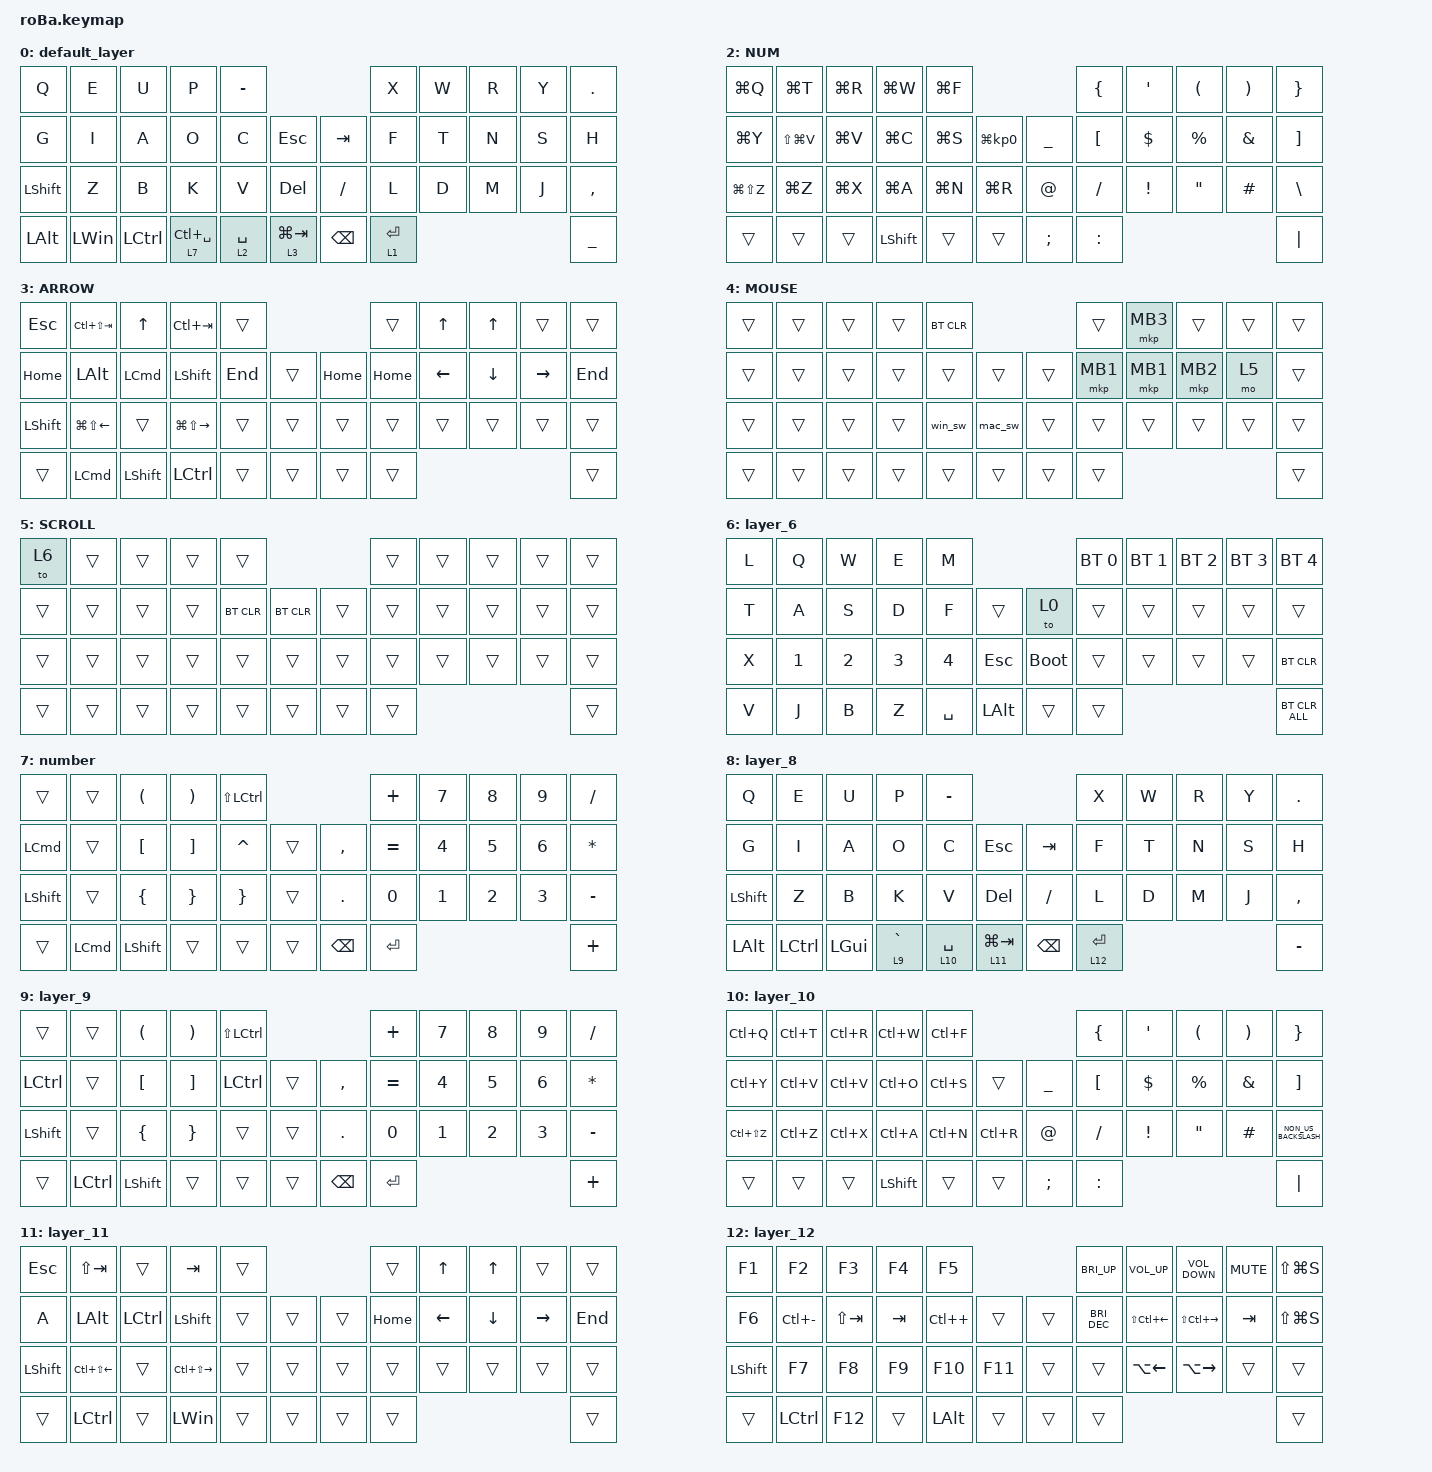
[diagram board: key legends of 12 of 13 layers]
#include <behaviors.dtsi>
#include <dt-bindings/zmk/bt.h>
#include <dt-bindings/zmk/keys.h>
#include <dt-bindings/zmk/pointing.h>

&mt {
    flavor = "balanced";
    quick-tap-ms = <0>;
};

&trackball {
    automouse-layer = <4>;
    scroll-layers = <5>;

    // arrows {
    //     layers = <3>;
    //     bindings =
    //         <&kp RIGHT_ARROW>,
    //         <&kp LEFT_ARROW>,
    //         <&kp UP_ARROW>,
    //         <&kp DOWN_ARROW>;
    //     tick = <10>;
    //     wait-ms = <5>;
    //     tap-ms = <5>;
    // };
};

/ {
    combos { compatible = "zmk,combos"; };

    macros {
        to_layer_0: to_layer_0 {
            compatible = "zmk,behavior-macro-one-param";
            #binding-cells = <1>;
            bindings = <&to 0 &macro_param_1to1 &kp MACRO_PLACEHOLDER>;
            label = "TO_LAYER_0";
        };

        mac_sw: mac_sw {
            compatible = "zmk,behavior-macro";
            #binding-cells = <0>;
            bindings = <&bt BT_SEL 0 &to 0>;
            label = "MAC_SW";
        };

        win_sw: win_sw {
            compatible = "zmk,behavior-macro";
            #binding-cells = <0>;
            bindings = <&bt BT_SEL 1 &to 8>;
            label = "WIN_SW";
        };
    };

    behaviors {
        lt_to_layer_0: lt_to_layer_0 {
            compatible = "zmk,behavior-hold-tap";
            label = "LAYER_TAP_TO_0";
            bindings = <&mo>, <&to_layer_0>;

            #binding-cells = <2>;
            tapping-term-ms = <200>;
        };
    };

    keymap {
        compatible = "zmk,keymap";

        default_layer {
            bindings = <
&kp Q           &kp E         &kp U             &kp P                       &kp MINUS                                                            &kp X                   &kp W  &kp R  &kp Y  &kp PERIOD
&kp G           &kp I         &kp A             &kp O                       &kp C                   &kp ESCAPE                    &kp TAB        &kp F                   &kp T  &kp N  &kp S  &kp H
&kp LEFT_SHIFT  &kp Z         &kp B             &kp K                       &kp V                   &kp DEL                       &kp SLASH      &kp L                   &kp D  &kp M  &kp J  &kp COMMA
&kp LEFT_ALT    &kp LEFT_WIN  &kp LEFT_CONTROL  &lt_to_layer_0 7 LC(SPACE)  &lt_to_layer_0 2 SPACE  &lt_to_layer_0 3 LG(TAB)      &kp BACKSPACE  &lt_to_layer_0 1 ENTER                       &kp UNDERSCORE
            >;

            sensor-bindings = <&inc_dec_kp LG(LEFT_BRACKET) LG(RIGHT_BRACKET)>;
        };

        FUNCTION {
            bindings = <
&kp F1          &kp F2            &kp F3       &kp F4   &kp F5                                           &kp C_BRI_UP        &kp C_VOL_UP          &kp C_VOL_DN           &kp K_MUTE        &kp LG(LS(NUMBER_4))
&kp F6          &kp LG(MINUS)     &kp LS(TAB)  &kp TAB  &kp LG(PLUS)      &kp F11      &kp F13           &kp C_BRI_DN        &kp LC(LEFT_ARROW)    &kp LC(RIGHT_ARROW)    &kp LC(UP_ARROW)  &kp LS(LC(LG(NUMBER_4)))
&kp LEFT_SHIFT  &kp F7            &kp F8       &kp F9   &kp F10           &kp F11      &kp LC(UP_ARROW)  &kp LC(LEFT_ARROW)  &kp LG(LEFT_BRACKET)  &kp LG(RIGHT_BRACKET)  &kp LG(W)         &trans
&trans          &kp LEFT_COMMAND  &kp F12      &trans   &kp LEFT_COMMAND  &trans       &kp LC(UP_ARROW)  &trans                                                                             &trans
            >;

            sensor-bindings = <&inc_dec_kp LS(TAB) TAB>;
        };

        NUM {
            bindings = <
&kp LG(Q)      &kp LG(T)      &kp LG(R)  &kp LG(W)       &kp LG(F)                                           &kp LEFT_BRACE    &kp SQT          &kp LEFT_PARENTHESIS  &kp RIGHT_PARENTHESIS  &kp RIGHT_BRACE
&kp LG(Y)      &kp LS(LG(V))  &kp LG(V)  &kp LG(C)       &kp LG(S)  &kp LG(KP_NUMBER_0)      &kp UNDERSCORE  &kp LEFT_BRACKET  &kp DOLLAR       &kp PERCENT           &kp AMPERSAND          &kp RIGHT_BRACKET
&kp LG(LS(Z))  &kp LG(Z)      &kp LG(X)  &kp LG(A)       &kp LG(N)  &kp LG(R)                &kp AT          &kp SLASH         &kp EXCLAMATION  &kp DOUBLE_QUOTES     &kp HASH               &kp BACKSLASH
&trans         &trans         &trans     &kp LEFT_SHIFT  &trans     &trans                   &kp SEMICOLON   &kp COLON                                                                       &kp PIPE
            >;

            sensor-bindings = <&inc_dec_kp LG(Z) LG(LS(Z))>;
        };

        ARROW {
            bindings = <
&kp ESCAPE      &kp LC(LS(TAB))         &kp UP_ARROW      &kp LC(TAB)              &trans                         &trans    &kp UP_ARROW    &kp UP_ARROW    &trans           &trans
&kp HOME        &kp LEFT_ALT            &kp LEFT_COMMAND  &kp LEFT_SHIFT           &kp END  &trans      &kp HOME  &kp HOME  &kp LEFT_ARROW  &kp DOWN_ARROW  &kp RIGHT_ARROW  &kp END
&kp LEFT_SHIFT  &kp LG(LS(LEFT_ARROW))  &trans            &kp LG(LS(RIGHT_ARROW))  &trans   &trans      &trans    &trans    &trans          &trans          &trans           &trans
&trans          &kp LEFT_COMMAND        &kp LSHIFT        &kp LEFT_CONTROL         &trans   &trans      &trans    &trans                                                     &trans
            >;

            sensor-bindings = <&inc_dec_kp PAGE_DOWN PAGE_UP>;
        };

        MOUSE {
            bindings = <
&trans  &trans  &trans  &trans  &bt BT_CLR                       &trans    &mkp MB3  &trans    &trans  &trans
&trans  &trans  &trans  &trans  &trans      &trans       &trans  &mkp MB1  &mkp MB1  &mkp MB2  &mo 5   &trans
&trans  &trans  &trans  &trans  &win_sw     &mac_sw      &trans  &trans    &trans    &trans    &trans  &trans
&trans  &trans  &trans  &trans  &trans      &trans       &trans  &trans                                &trans
            >;
        };

        SCROLL {
            bindings = <
&to 6   &trans  &trans  &trans  &trans                              &trans  &trans  &trans  &trans  &trans
&trans  &trans  &trans  &trans  &bt BT_CLR  &bt BT_CLR      &trans  &trans  &trans  &trans  &trans  &trans
&trans  &trans  &trans  &trans  &trans      &trans          &trans  &trans  &trans  &trans  &trans  &trans
&trans  &trans  &trans  &trans  &trans      &trans          &trans  &trans                          &trans
            >;
        };

        layer_6 {
            bindings = <
&kp L  &kp Q         &kp W         &kp E         &kp M                                        &bt BT_SEL 0  &bt BT_SEL 1  &bt BT_SEL 2  &bt BT_SEL 3  &bt BT_SEL 4
&kp T  &kp A         &kp S         &kp D         &kp F         &trans            &to 0        &trans        &trans        &trans        &trans        &trans
&kp X  &kp NUMBER_1  &kp NUMBER_2  &kp NUMBER_3  &kp NUMBER_4  &kp ESC           &bootloader  &trans        &trans        &trans        &trans        &bt BT_CLR
&kp V  &kp J         &kp B         &kp Z         &kp SPACE     &kp LEFT_ALT      &trans       &trans                                                  &bt BT_CLR_ALL
            >;
        };

        number {
            bindings = <
&trans            &trans            &kp LEFT_PARENTHESIS  &kp RIGHT_PARENTHESIS  &kp LS(LCTRL)                               &kp PLUS      &kp NUMBER_7  &kp NUMBER_8  &kp NUMBER_9  &kp SLASH
&kp LEFT_COMMAND  &trans            &kp LEFT_BRACKET      &kp RIGHT_BRACKET      &kp CARET        &trans      &kp COMMA      &kp EQUAL     &kp NUMBER_4  &kp NUMBER_5  &kp NUMBER_6  &kp ASTERISK
&kp LEFT_SHIFT    &trans            &kp LEFT_BRACE        &kp RIGHT_BRACE        &kp RIGHT_BRACE  &trans      &kp PERIOD     &kp NUMBER_0  &kp NUMBER_1  &kp NUMBER_2  &kp NUMBER_3  &kp MINUS
&trans            &kp LEFT_COMMAND  &kp LEFT_SHIFT        &trans                 &trans           &trans      &kp BACKSPACE  &kp ENTER                                               &kp PLUS
            >;
        };

        layer_8 {
            bindings = <
&kp Q      &kp E      &kp U     &kp P                   &kp MINUS                                                         &kp X                    &kp W  &kp R  &kp Y  &kp DOT
&kp G      &kp I      &kp A     &kp O                   &kp C                    &kp ESC                        &kp TAB   &kp F                    &kp T  &kp N  &kp S  &kp H
&kp LSHFT  &kp Z      &kp B     &kp K                   &kp V                    &kp DEL                        &kp FSLH  &kp L                    &kp D  &kp M  &kp J  &kp COMMA
&kp LALT   &kp LCTRL  &kp LGUI  &lt_to_layer_0 9 GRAVE  &lt_to_layer_0 10 SPACE  &lt_to_layer_0 11 LG(TAB)      &kp BSPC  &lt_to_layer_0 12 ENTER                       &kp MINUS
            >;

            sensor-bindings = <&inc_dec_kp LA(LEFT_ARROW) LA(RIGHT_ARROW)>;
        };

        layer_9 {
            bindings = <
&trans            &trans            &kp LEFT_PARENTHESIS  &kp RIGHT_PARENTHESIS  &kp LS(LCTRL)                         &kp PLUS   &kp N7  &kp N8  &kp N9  &kp FSLH
&kp LEFT_CONTROL  &trans            &kp LEFT_BRACKET      &kp RIGHT_BRACKET      &kp LCTRL      &trans      &kp COMMA  &kp EQUAL  &kp N4  &kp N5  &kp N6  &kp ASTERISK
&kp LEFT_SHIFT    &trans            &kp LEFT_BRACE        &kp RIGHT_BRACE        &trans         &trans      &kp DOT    &kp N0     &kp N1  &kp N2  &kp N3  &kp MINUS
&trans            &kp LEFT_CONTROL  &kp LEFT_SHIFT        &trans                 &trans         &trans      &kp BSPC   &kp ENTER                          &kp PLUS
            >;
        };

        layer_10 {
            bindings = <
&kp LC(Q)      &kp LC(T)  &kp LC(R)  &kp LC(W)       &kp LC(F)                                 &kp LEFT_BRACE  &kp SQT          &kp LEFT_PARENTHESIS  &kp RIGHT_PARENTHESIS  &kp RIGHT_BRACE
&kp LC(Y)      &kp LC(V)  &kp LC(V)  &kp LC(O)       &kp LC(S)  &trans         &kp UNDERSCORE  &kp LBKT        &kp DOLLAR       &kp PERCENT           &kp AMPERSAND          &kp RIGHT_BRACKET
&kp LC(LS(Z))  &kp LC(Z)  &kp LC(X)  &kp LC(A)       &kp LC(N)  &kp LC(R)      &kp AT_SIGN     &kp FSLH        &kp EXCLAMATION  &kp DOUBLE_QUOTES     &kp HASH               &kp NON_US_BACKSLASH
&trans         &trans     &trans     &kp LEFT_SHIFT  &trans     &trans         &kp SEMI        &kp COLON                                                                     &kp PIPE
            >;
        };

        layer_11 {
            bindings = <
&kp ESC         &kp LS(TAB)             &trans            &kp TAB                  &trans                      &trans    &kp UP    &kp UP    &trans     &trans
&kp A           &kp LEFT_ALT            &kp LEFT_CONTROL  &kp LEFT_SHIFT           &trans  &trans      &trans  &kp HOME  &kp LEFT  &kp DOWN  &kp RIGHT  &kp END
&kp LEFT_SHIFT  &kp LC(LS(LEFT_ARROW))  &trans            &kp LC(LS(RIGHT_ARROW))  &trans  &trans      &trans  &trans    &trans    &trans    &trans     &trans
&trans          &kp LEFT_CONTROL        &trans            &kp LEFT_WIN             &trans  &trans      &trans  &trans                                   &trans
            >;
        };

        layer_12 {
            bindings = <
&kp F1     &kp F2         &kp F3       &kp F4   &kp F5                             &kp C_BRI_UP   &kp C_VOL_UP        &kp C_VOLUME_DOWN    &kp K_MUTE  &kp LS(LG(S))
&kp F6     &kp LC(MINUS)  &kp LS(TAB)  &kp TAB  &kp LC(PLUS)  &trans       &trans  &kp C_BRI_DEC  &kp LS(LC(LEFT))    &kp LS(LC(RIGHT))    &kp TAB     &kp LS(LG(S))
&kp LSHFT  &kp F7         &kp F8       &kp F9   &kp F10       &kp F11      &trans  &trans         &kp LA(LEFT_ARROW)  &kp LA(RIGHT_ARROW)  &trans      &trans
&trans     &kp LCTRL      &kp F12      &trans   &kp LALT      &trans       &trans  &trans                                                              &trans
            >;

            sensor-bindings = <&inc_dec_kp LS(TAB) TAB>;
        };
    };
};
